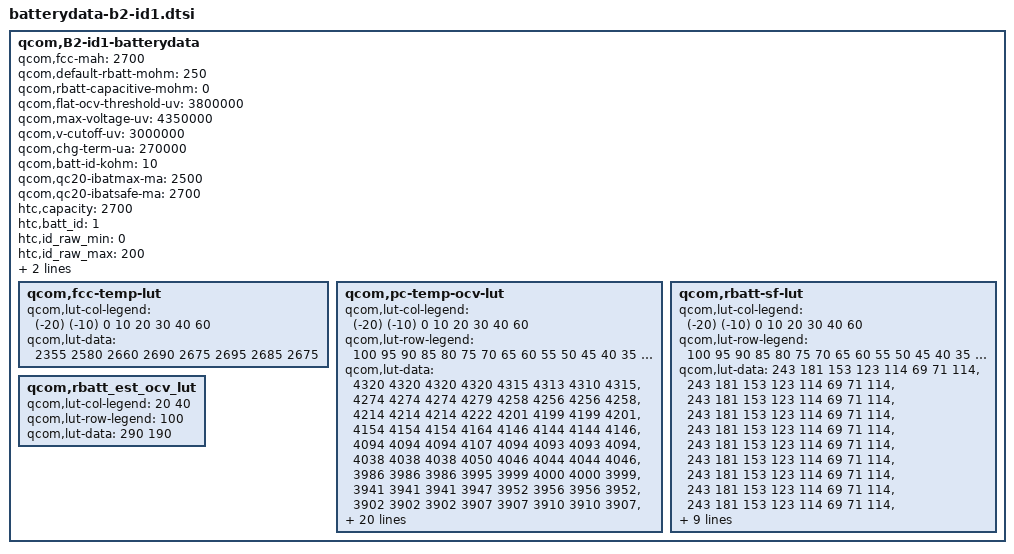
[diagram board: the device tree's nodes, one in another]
	qcom,B2-id1-batterydata {
	qcom,fcc-mah = <2700>;
	qcom,default-rbatt-mohm = <250>;
	qcom,rbatt-capacitive-mohm = <0>;
	qcom,flat-ocv-threshold-uv = <3800000>;
	qcom,max-voltage-uv = <4350000>;
	qcom,v-cutoff-uv = <3000000>;
	qcom,chg-term-ua = <270000>;
	qcom,batt-id-kohm = <10>;
	qcom,qc20-ibatmax-ma = <2500>;
	qcom,qc20-ibatsafe-ma = <2700>;
	htc,capacity = <2700>;
	htc,batt_id = <1>;
	htc,id_raw_min = <0>;
	htc,id_raw_max = <200>;
	htc,type = <1>;
	htc,model_name = "B0P6B100";

	qcom,fcc-temp-lut {
		qcom,lut-col-legend = <(-20) (-10) 0 10 20 30 40 60>;
		qcom,lut-data = <2355 2580 2660 2690 2675 2695 2685 2675>;
	};

	qcom,pc-temp-ocv-lut {
		qcom,lut-col-legend = <(-20) (-10) 0 10 20 30 40 60>;
		qcom,lut-row-legend = <100 95 90 85 80 75 70 65 60 55 50 45 40 35 30 25 20 15 10 9 8 7 6 5 4 3 2 1 0>;
		qcom,lut-data = <4320 4320 4320 4320 4315 4313 4310 4315>,
				<4274 4274 4274  4279  4258  4256 4256  4258 >,
				<4214 4214 4214  4222  4201  4199 4199  4201 >,
				<4154 4154 4154  4164  4146  4144 4144  4146 >,
				<4094 4094 4094  4107  4094  4093 4093  4094 >,
				<4038 4038 4038  4050  4046  4044 4044  4046 >,
				<3986 3986 3986  3995  3999  4000 4000  3999 >,
				<3941 3941 3941  3947  3952  3956 3956  3952 >,
				<3902 3902 3902  3907  3907  3910 3910  3907 >,
				<3867 3867 3867  3873  3870  3870 3870  3870 >,
				<3837 3837 3837  3843  3842  3841 3841  3842 >,
				<3810 3810 3810  3817  3820  3819 3819  3820 >,
				<3786 3786 3786  3794  3801  3801 3801  3801 >,
				<3764 3764 3764  3773  3786  3786 3786  3786 >,
				<3745 3745 3745  3753  3771  3770 3770  3771 >,
				<3724 3724 3724  3731  3755  3749 3749  3755 >,
				<3706 3706 3706  3704  3735  3728 3728  3735 >,
				<3676 3676 3676  3675  3705  3698 3698  3705 >,
				<3646 3646 3646  3614  3674  3671 3671  3674 >,
				<3599 3599 3599  3554  3670  3666 3666  3670 >,
				<3553 3553 3553  3495  3665  3661 3661  3665 >,
				<3465 3465 3465  3374  3655  3644 3644  3655 >,
				<3378 3378 3378  3253  3646  3628 3628  3646 >,
				<3315 3315 3315  3211  3608  3577 3577  3608 >,
				<3252 3252 3252  3168  3570  3527 3527  3570 >,
				<3189 3189 3189  3126  3498  3436 3436  3498 >,
				<3126 3126 3126  3084  3427  3345 3345  3427 >,
				<3063 3063 3063  3042  3213  3073 3172  3213 >,
				<3000 3000 3000  3000  3000  3000 3000  3000 >;
	};

	qcom,rbatt-sf-lut {
		qcom,lut-col-legend = <(-20) (-10) 0 10 20 30 40 60>;
		qcom,lut-row-legend = <100 95 90 85 80 75 70 65 60 55 50 45 40 35 30 25 20 15 10>;
		qcom,lut-data = <243 181 153 123 114 69 71 114>,
                                        <243 181 153 123 114 69 71 114>,
                                        <243 181 153 123 114 69 71 114>,
                                        <243 181 153 123 114 69 71 114>,
                                        <243 181 153 123 114 69 71 114>,
                                        <243 181 153 123 114 69 71 114>,
                                        <243 181 153 123 114 69 71 114>,
                                        <243 181 153 123 114 69 71 114>,
                                        <243 181 153 123 114 69 71 114>,
                                        <243 181 153 123 114 69 71 114>,
                                        <243 181 153 123 114 69 71 114>,
                                        <243 181 153 123 114 69 71 114>,
                                        <243 181 153 123 114 69 71 114>,
                                        <243 181 153 123 114 69 71 114>,
                                        <243 181 153 123 114 69 71 114>,
                                        <243 181 153 123 114 69 71 114>,
                                        <243 181 153 123 114 69 71 114>,
                                        <243 181 153 123 114 69 71 114>,
                                        <243 181 153 123 114 69 71 114>;
		};

	qcom,rbatt_est_ocv_lut {
		qcom,lut-col-legend = <20 40>;
		qcom,lut-row-legend = <100>;
		qcom,lut-data = <290 190>;
		};
	};
